# N32WB03X register map
Vendor: Nationstech Ltd.; File version: 1.0
Registers are 32-bit, read-write, reset 0x0 unless marked. A register's access mark holds for its fields unless they carry their own. Offsets are from the block's base; [hi:lo] are bit positions; {n}, {i} and the like mark numbered series.

## RTC — Real time clock
Base 0x40002800
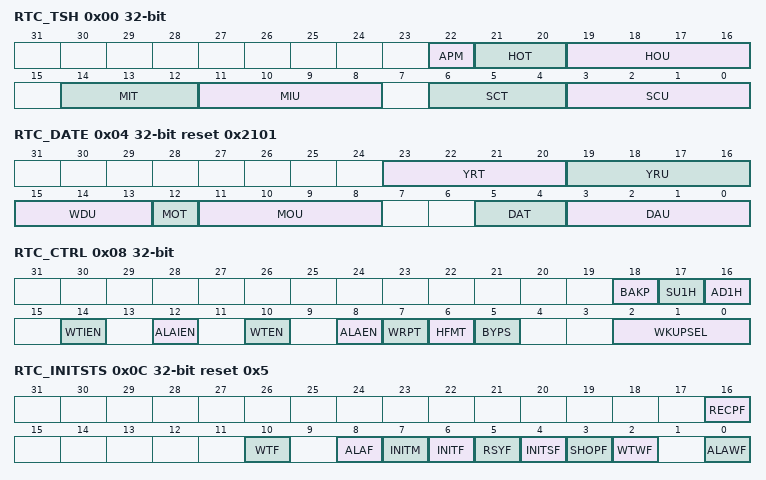
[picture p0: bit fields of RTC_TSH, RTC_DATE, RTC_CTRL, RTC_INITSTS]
0x00 RTC_TSH
  [22] APM, [21:20] HOT, [19:16] HOU, [14:12] MIT, [11:8] MIU, [6:4] SCT, [3:0] SCU
0x04 RTC_DATE reset 0x2101
  [23:20] YRT, [19:16] YRU, [15:13] WDU, [12] MOT, [11:8] MOU, [5:4] DAT, [3:0] DAU
0x08 RTC_CTRL
  [18] BAKP, [17] SU1H, [16] AD1H, [14] WTIEN, [12] ALAIEN, [10] WTEN, [8] ALAEN, [7] WRPT, [6] HFMT, [5] BYPS, [2:0] WKUPSEL
0x0C RTC_INITSTS reset 0x5
  [16] RECPF, [10] WTF, [8] ALAF, [7] INITM, [6] INITF, [5] RSYF, [4] INITSF, [3] SHOPF, [2] WTWF, [0] ALAWF
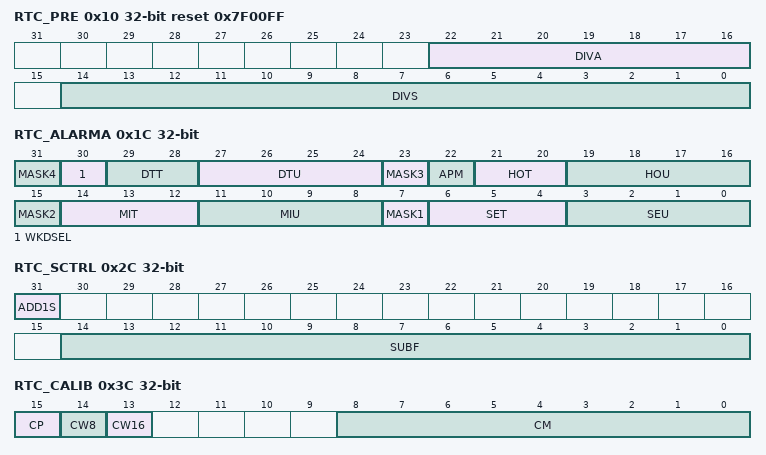
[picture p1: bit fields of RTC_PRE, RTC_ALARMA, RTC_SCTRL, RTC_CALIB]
0x10 RTC_PRE reset 0x7F00FF
  [22:16] DIVA, [14:0] DIVS
0x14 RTC_WKUPT reset 0xFFFF
  [15:0] WKUPT
0x1C RTC_ALARMA
  [8n-1] MASK{n} (n=1..4), [30] WKDSEL, [29:28] DTT, [27:24] DTU, [22] APM, [21:20] HOT, [19:16] HOU, [14:12] MIT, [11:8] MIU, [6:4] SET, [3:0] SEU
0x24 RTC_WRP
  [7:0] PKEY
0x28 RTC_SUBS
  [15:0] SS
0x2C RTC_SCTRL
  [31] ADD1S
  [14:0] SUBF — SUB1S
0x3C RTC_CALIB
  [15] CP, [14] CW8, [13] CW16, [8:0] CM
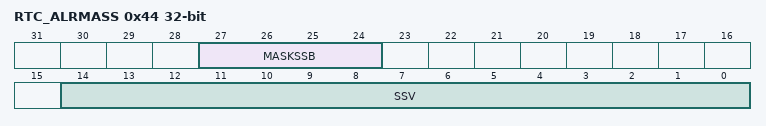
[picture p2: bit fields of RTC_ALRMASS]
0x44 RTC_ALRMASS
  [27:24] MASKSSB, [14:0] SSV

## SPI1 — Serial peripheral interface
Base 0x40012000
Same registers: SPI2 0x40014400
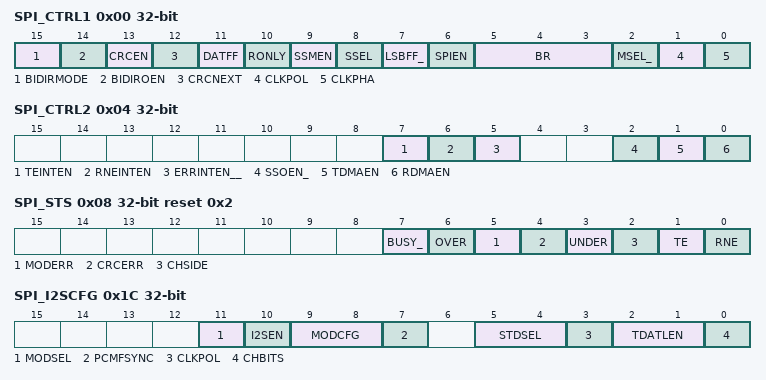
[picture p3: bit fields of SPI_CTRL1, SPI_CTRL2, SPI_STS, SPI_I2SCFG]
0x00 SPI_CTRL1
  [15] BIDIRMODE, [14] BIDIROEN, [13] CRCEN, [12] CRCNEXT, [11] DATFF, [10] RONLY, [9] SSMEN, [8] SSEL, [7] LSBFF_, [6] SPIEN, [5:3] BR, [2] MSEL_, [1] CLKPOL, [0] CLKPHA
0x04 SPI_CTRL2
  [7] TEINTEN, [6] RNEINTEN, [5] ERRINTEN__, [2] SSOEN_, [1] TDMAEN, [0] RDMAEN
0x08 SPI_STS reset 0x2
  [7] BUSY_, [6] OVER, [5] MODERR, [4] CRCERR, [3] UNDER, [2] CHSIDE, [1] TE, [0] RNE
0x0C SPI_DAT
  [15:0] DAT
0x10 SPI_CRCPOLY
  [15:0] CRCPOLY
0x14 SPI_CRCRDAT
  [15:0] CRCRDAT
0x18 SPI_CRCTDAT
  [15:0] CRCTDAT
0x1C SPI_I2SCFG
  [11] MODSEL, [10] I2SEN, [9:8] MODCFG, [7] PCMFSYNC, [5:4] STDSEL, [3] CLKPOL, [2:1] TDATLEN, [0] CHBITS
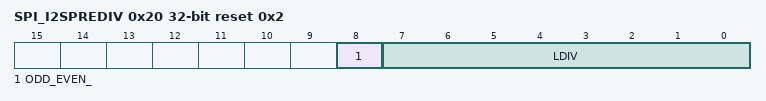
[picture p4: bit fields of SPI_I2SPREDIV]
0x20 SPI_I2SPREDIV reset 0x2
  [8] ODD_EVEN_, [7:0] LDIV

## TIM1 — Advanced timer
Base 0x40012C00
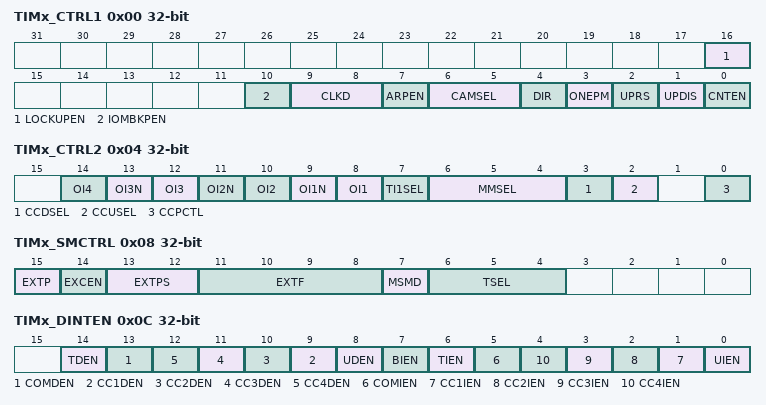
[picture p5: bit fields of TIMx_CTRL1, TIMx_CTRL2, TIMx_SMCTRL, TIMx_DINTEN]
0x00 TIMx_CTRL1
  [16] LOCKUPEN, [10] IOMBKPEN, [9:8] CLKD, [7] ARPEN, [6:5] CAMSEL, [4] DIR, [3] ONEPM, [2] UPRS, [1] UPDIS, [0] CNTEN
0x04 TIMx_CTRL2
  [2n+6] OI{n} (n=1..4), [13] OI3N, [11] OI2N, [9] OI1N, [7] TI1SEL, [6:4] MMSEL, [3] CCDSEL, [2] CCUSEL, [0] CCPCTL
0x08 TIMx_SMCTRL
  [15] EXTP, [14] EXCEN, [13:12] EXTPS, [11:8] EXTF, [7] MSMD, [6:4] TSEL
0x0C TIMx_DINTEN
  [14] TDEN, [13] COMDEN, [n+8] CC{n}DEN (n=1..4), [8] UDEN, [7] BIEN, [6] TIEN, [5] COMIEN, [n] CC{n}IEN (n=1..4), [0] UIEN
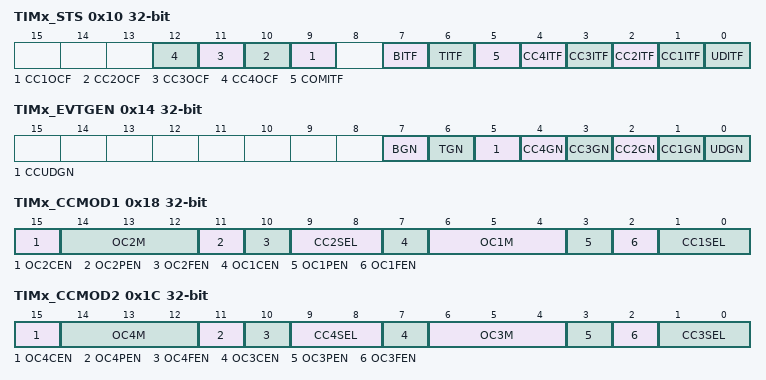
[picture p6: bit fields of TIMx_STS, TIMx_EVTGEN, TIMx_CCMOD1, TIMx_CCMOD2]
0x10 TIMx_STS (reset mask 0xEFF)
  [n+8] CC{n}OCF (n=1..4), [7] BITF, [6] TITF, [5] COMITF, [n] CC{n}ITF (n=1..4), [0] UDITF
0x14 TIMx_EVTGEN
  [7] BGN, [6] TGN, [5] CCUDGN, [n] CC{n}GN (n=1..4), [0] UDGN
0x18 TIMx_CCMOD1
  [15] OC2CEN, [14:12] OC2M, [11] OC2PEN, [10] OC2FEN, [9:8] CC2SEL, [7] OC1CEN, [6:4] OC1M, [3] OC1PEN, [2] OC1FEN, [1:0] CC1SEL
0x1C TIMx_CCMOD2
  [15] OC4CEN, [14:12] OC4M, [11] OC4PEN, [10] OC4FEN, [9:8] CC4SEL, [7] OC3CEN, [6:4] OC3M, [3] OC3PEN, [2] OC3FEN, [1:0] CC3SEL
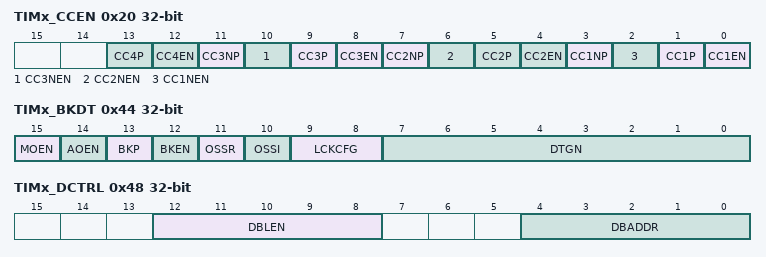
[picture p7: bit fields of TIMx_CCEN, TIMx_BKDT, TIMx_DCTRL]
0x20 TIMx_CCEN
  [4n-3] CC{n}P (n=1..4), [4n-4] CC{n}EN (n=1..4), [11] CC3NP, [10] CC3NEN, [7] CC2NP, [6] CC2NEN, [3] CC1NP, [2] CC1NEN
0x24 TIMx_CNT
  [15:0] CNT
0x28 TIMx_PSC
  [15:0] PSC
0x2C TIMx_AR
  [15:0] AR
0x30 TIMx_REPCNT
  [7:0] REPCNT
{0x30+4i} TIMx_CCDAT{i} (i=1..4)
  [15:0] CCDAT{i}
0x44 TIMx_BKDT
  [15] MOEN, [14] AOEN, [13] BKP, [12] BKEN, [11] OSSR, [10] OSSI, [9:8] LCKCFG, [7:0] DTGN
0x48 TIMx_DCTRL
  [12:8] DBLEN, [4:0] DBADDR
0x4C TIMx_DADDR
  [15:0] BURST

## TIM3 — General purpose timer
Base 0x40000400
Registers as TIM1, without TIMx_REPCNT, TIMx_BKDT; these are added or differ:
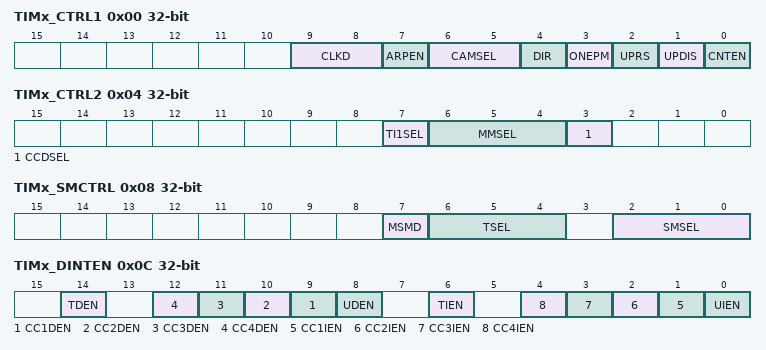
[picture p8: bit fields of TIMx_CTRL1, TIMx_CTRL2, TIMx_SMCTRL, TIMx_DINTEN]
0x00 TIMx_CTRL1
  [9:8] CLKD, [7] ARPEN, [6:5] CAMSEL, [4] DIR, [3] ONEPM, [2] UPRS, [1] UPDIS, [0] CNTEN
0x04 TIMx_CTRL2
  [7] TI1SEL, [6:4] MMSEL, [3] CCDSEL
0x08 TIMx_SMCTRL
  [7] MSMD, [6:4] TSEL, [2:0] SMSEL
0x0C TIMx_DINTEN
  [14] TDEN, [n+8] CC{n}DEN (n=1..4), [8] UDEN, [6] TIEN, [n] CC{n}IEN (n=1..4), [0] UIEN
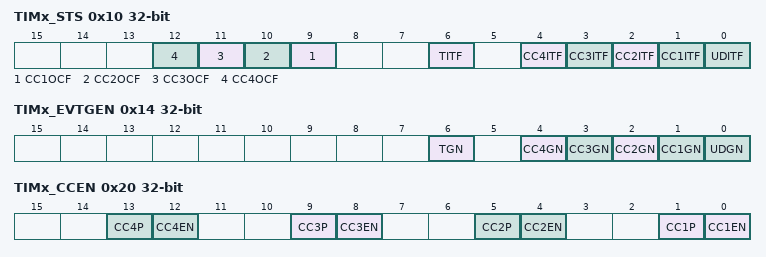
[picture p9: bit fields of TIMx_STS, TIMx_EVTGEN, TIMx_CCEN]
0x10 TIMx_STS
  [n+8] CC{n}OCF (n=1..4), [6] TITF, [n] CC{n}ITF (n=1..4), [0] UDITF
0x14 TIMx_EVTGEN
  [6] TGN, [n] CC{n}GN (n=1..4), [0] UDGN
0x20 TIMx_CCEN
  [4n-3] CC{n}P (n=1..4), [4n-4] CC{n}EN (n=1..4)

## TIM6 — Basic timer
Base 0x40001000
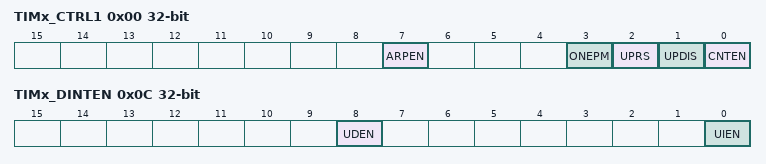
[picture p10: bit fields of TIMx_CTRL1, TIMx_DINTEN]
0x00 TIMx_CTRL1
  [7] ARPEN, [3] ONEPM, [2] UPRS, [1] UPDIS, [0] CNTEN
0x04 TIMx_CTRL2
  [6:4] MMSEL
0x0C TIMx_DINTEN
  [8] UDEN, [0] UIEN
0x10 TIMx_STS
  [0] UDITF
0x14 TIMx_EVTGEN
  [0] UDGN
0x24 TIMx_CNT
  [15:0] CNT
0x28 TIMx_PSC
  [15:0] PSC
0x2C TIMx_AR
  [15:0] AR

## USART1 — Universal synchronous asynchronous receiver transmitter
Base 0x40013800
Same registers: USART2 0x40004400
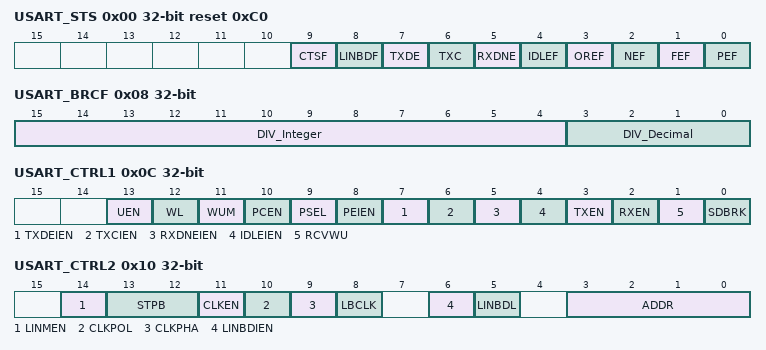
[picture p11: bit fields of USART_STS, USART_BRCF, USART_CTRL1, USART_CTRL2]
0x00 USART_STS reset 0xC0
  [9] CTSF, [8] LINBDF, [7] TXDE, [6] TXC, [5] RXDNE, [4] IDLEF, [3] OREF, [2] NEF, [1] FEF, [0] PEF
0x04 USART_DAT
  [8:0] DATV
0x08 USART_BRCF
  [15:4] DIV_Integer, [3:0] DIV_Decimal
0x0C USART_CTRL1
  [13] UEN, [12] WL, [11] WUM, [10] PCEN, [9] PSEL, [8] PEIEN, [7] TXDEIEN, [6] TXCIEN, [5] RXDNEIEN, [4] IDLEIEN, [3] TXEN, [2] RXEN, [1] RCVWU, [0] SDBRK
0x10 USART_CTRL2
  [14] LINMEN, [13:12] STPB, [11] CLKEN, [10] CLKPOL, [9] CLKPHA, [8] LBCLK, [6] LINBDIEN, [5] LINBDL, [3:0] ADDR
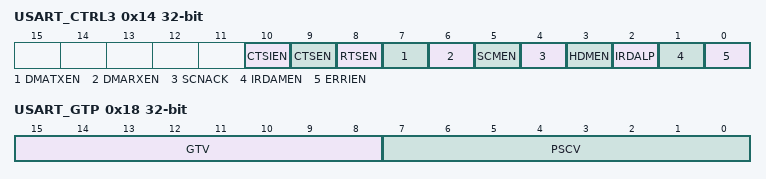
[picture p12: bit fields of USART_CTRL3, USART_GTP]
0x14 USART_CTRL3
  [10] CTSIEN, [9] CTSEN, [8] RTSEN, [7] DMATXEN, [6] DMARXEN, [5] SCMEN, [4] SCNACK, [3] HDMEN, [2] IRDALP, [1] IRDAMEN, [0] ERRIEN
0x18 USART_GTP
  [15:8] GTV, [7:0] PSCV

## WWDG — window watchdog
Base 0x40002C00
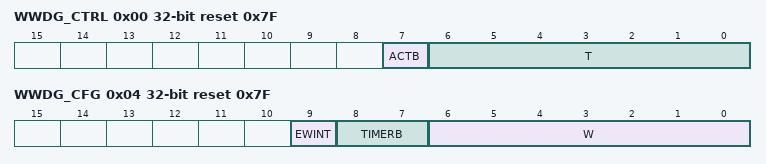
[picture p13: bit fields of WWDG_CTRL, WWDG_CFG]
0x00 WWDG_CTRL reset 0x7F
  [7] ACTB, [6:0] T
0x04 WWDG_CFG reset 0x7F
  [9] EWINT, [8:7] TIMERB, [6:0] W
0x08 WWDG_STS
  [0] EWINTF
